# Montana register map
Vendor: ONSemiconductor; Series: Montana Series; File version: 1.0
CPU: CM33 r0p4, little endian, MPU, FPU, 3 interrupt priority bits
Registers are 32-bit, read-write, reset 0x0 unless marked. A register's access mark holds for its fields unless they carry their own. Offsets are from the block's base; [hi:lo] are bit positions; {n}, {i} and the like mark numbered series.

## RESET
Base 0x40000200
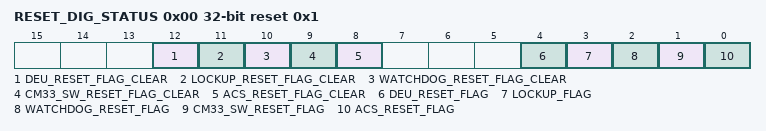
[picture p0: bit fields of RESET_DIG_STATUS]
0x00 RESET_DIG_STATUS reset 0x1 (reset mask 0x1F) — Reset status register
  [12] DEU_RESET_FLAG_CLEAR wo — Reset the sticky DEU reset flag
    1=DEU_RESET_FLAG_CLEAR (Reset the sticky DEU reset flag)
  [11] LOCKUP_RESET_FLAG_CLEAR wo — Reset the sticky LOCKUP flag
    1=LOCKUP_FLAG_CLEAR (Reset the sticky LOCKUP flag)
  [10] WATCHDOG_RESET_FLAG_CLEAR wo — Reset the sticky Watchdog time-out reset flag
    1=WATCHDOG_RESET_FLAG_CLEAR (Reset the sticky Watchdog time-out reset flag)
  [9] CM33_SW_RESET_FLAG_CLEAR wo — Reset the sticky CM33 software reset flag
    1=CM33_SW_RESET_FLAG_CLEAR (Reset the sticky CM33 software reset flag)
  [8] ACS_RESET_FLAG_CLEAR wo — Reset the sticky ACS reset flag
    1=ACS_RESET_FLAG_CLEAR (Reset the sticky ACS reset flag)
  [4] DEU_RESET_FLAG ro — Sticky flag that detect that a DEU reset occured
    0=DEU_RESET_NOT_SET (The DEU reset has not triggered at least once.); 1=DEU_RESET_SET (The DEU reset was triggered at least once since this status bit was last cleared)
  [3] LOCKUP_FLAG ro — Sticky flag that detects that a LOCKUP occurred
    0=LOCKUP_NOT_SET (The LOCKUP has not triggered at least once); 1=LOCKUP_SET (The LOCKUP was triggered at least once)
  [2] WATCHDOG_RESET_FLAG ro — Sticky flag that detects that a Watchdog time-out reset occurred
    0=WATCHDOG_RESET_NOT_SET (The Watchdog time-out reset has not triggered at least once); 1=WATCHDOG_RESET_SET (The Watchdog time-out reset was triggered at least once since this status bit was last cleared)
  [1] CM33_SW_RESET_FLAG ro — Sticky flag that detects that a CM33 software reset occurred
    0=CM33_SW_RESET_NOT_SET (The CM33 software system reset has not triggered at least once); 1=CM33_SW_RESET_SET (The CM33 software system reset was triggered at least once since this status bit was last cleared)
  [0] ACS_RESET_FLAG ro — Sticky flag that detects that a ACS reset occurred
    0=ACS_RESET_NOT_SET (The ACS reset has not triggered at least once); 1=ACS_RESET_SET (The ACS reset was triggered at least once since this status bit was last cleared)

## WATCHDOG — Watchdog Timer
Base 0x40000300
0x00 WATCHDOG_CFG reset 0xB — Watchdog timer Configuration Register
  [3:0] TIMEOUT_VALUE — Watchdog timeout period. Values 0xC to 0xF result in the same timeout period as the value 0xB.
    0=WATCHDOG_TIMEOUT_2M048 (2.048 ms); 1=WATCHDOG_TIMEOUT_4M096 (4.096 ms); 2=WATCHDOG_TIMEOUT_8M2 (8.192 ms); 3=WATCHDOG_TIMEOUT_16M4 (16.384 ms); 4=WATCHDOG_TIMEOUT_32M8 (32.768 ms); 5=WATCHDOG_TIMEOUT_65M5 (65.536 ms); 6=WATCHDOG_TIMEOUT_131M1 (131.072 ms); 7=WATCHDOG_TIMEOUT_262M1 (262.144 ms); 8=WATCHDOG_TIMEOUT_524M3 (524.3 ms); 9=WATCHDOG_TIMEOUT_1048M6 (1.048 sec); 10=WATCHDOG_TIMEOUT_2097M1 (2.097 sec); 11=WATCHDOG_TIMEOUT_4194M3 (4.194 sec)
0x04 WATCHDOG_CTRL reset not defined — Watchdog Refresh Control Register
  [31:0] WATCHDOG_REFRESH wo — Write a key to reset the watchdog
    0x2B1E211=WATCHDOG_REFRESH (Write 32-bit key to reset the watchdog (others values have no effect))
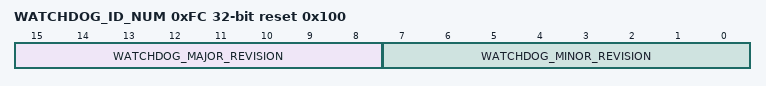
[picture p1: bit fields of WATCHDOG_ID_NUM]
0xFC WATCHDOG_ID_NUM ro reset 0x100 — WATCHDOG ID number
  [15:8] WATCHDOG_MAJOR_REVISION — WATCHDOG Major Revision number
    1=WATCHDOG_MAJOR_REVISION (Watchdog revision 1.0)
  [7:0] WATCHDOG_MINOR_REVISION — WATCHDOG Minor Revision number
    0=WATCHDOG_MINOR_REVISION (Watchdog revision 1.0)

## TIMER0 — General-Purpose Timers
Base 0x40000400
Same registers: TIMER1 0x40000500, TIMER2 0x40000600, TIMER3 0x40000700
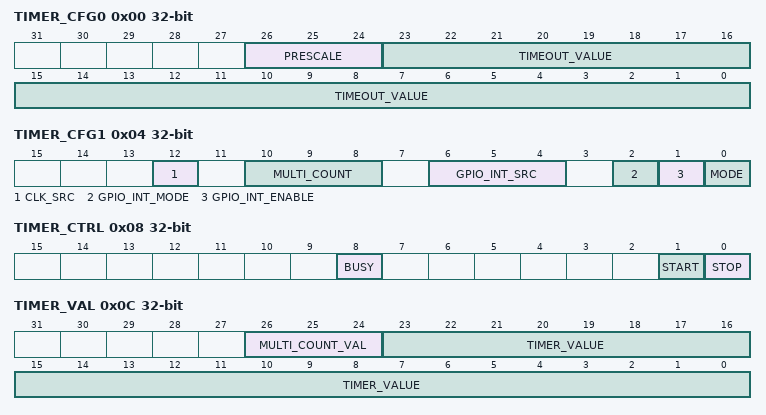
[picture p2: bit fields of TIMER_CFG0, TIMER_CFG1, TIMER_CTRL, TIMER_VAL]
0x00 TIMER_CFG0 — Timer Configuration 0 Register
  [26:24] PRESCALE — Prescale value of the timer
    0=TIMER_PRESCALE_1 (Divide the input clock frequency by 1); 1=TIMER_PRESCALE_2 (Divide the input clock frequency by 2); 2=TIMER_PRESCALE_4 (Divide the input clock frequency by 4); 3=TIMER_PRESCALE_8 (Divide the input clock frequency by 8); 4=TIMER_PRESCALE_16 (Divide the input clock frequency by 16); 5=TIMER_PRESCALE_32 (Divide the input clock frequency by 32); 6=TIMER_PRESCALE_64 (Divide the input clock frequency by 64); 7=TIMER_PRESCALE_128 (Divide the input clock frequency by 128)
  [23:0] TIMEOUT_VALUE — Number of Timer clock cycles to time-out
0x04 TIMER_CFG1 — Timer Configuration 1 Register
  [12] CLK_SRC — Clock source
    0=TIMER_SLOWCLK_DIV32 (Timer clock source is SLOWCLK divided by 32); 1=TIMER_SLOWCLK_DIV2 (Timer clock source is SLOWCLK divided by 2)
  [10:8] MULTI_COUNT — Multi-count value
    0=TIMER_MULTI_COUNT_1 (Stop on 1st Time-out occurrence and issue an interrupt); 1=TIMER_MULTI_COUNT_2 (Stop on 2nd Time-out occurrence and issue an interrupt); 2=TIMER_MULTI_COUNT_3 (Stop on 3rd Time-out occurrence and issue an interrupt); {v}=TIMER_MULTI_COUNT_{v+1} (Stop on {v+1}th Time-out occurrence and issue an interrupt) (v=3..7)
  [6:4] GPIO_INT_SRC — GPIO interrupt source selection
    {v}=TIMER_SRC_GPIO_INT{v} (Select GPIO interrupt defined in GPIO_INT_CFG{v}) (v=0..3)
  [2] GPIO_INT_MODE — GPIO interrupt capture mode
    0=TIMER_GPIO_INT_SINGLE (GPIO interrupt single capture mode); 1=TIMER_GPIO_INT_CONTINUOUS (GPIO interrupt continuous capture mode)
  [1] GPIO_INT_ENABLE — GPIO interrupt capture enable
    0=TIMER_GPIO_INT_DISABLE (Disable GPIO interrupt capture); 1=TIMER_GPIO_INT_ENABLE (Enable GPIO interrupt capture)
  [0] MODE — Timer mode
    0=TIMER_SHOT_MODE (One shot / multi shot mode); 1=TIMER_FREE_RUN (Free-run mode)
0x08 TIMER_CTRL (reset mask 0x100) — General-Purpose timer Control / Status Register
  [8] BUSY ro — Indicate if the timer is active or not
    0=TIMER_INACTIVE (The timer is inactive); 1=TIMER_ACTIVE (The timer is active)
  [1] START wo — Start or restart the timer
    1=TIMER_START (Writing a 1 starts or restarts the timer)
  [0] STOP wo — Stop the timer
    1=TIMER_STOP (Writing a 1 stops the timer)
0x0C TIMER_VAL ro — Timer Current Value Register
  [26:24] MULTI_COUNT_VAL — Current multi counter value
  [23:0] TIMER_VALUE — Current timer value
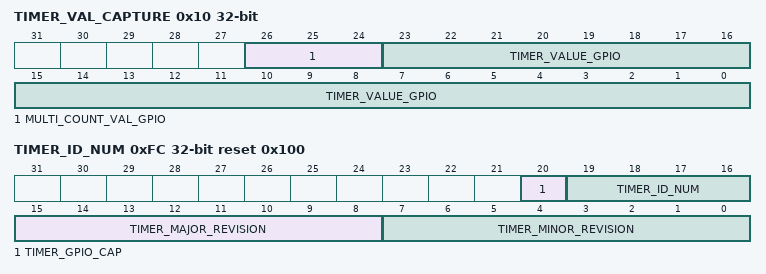
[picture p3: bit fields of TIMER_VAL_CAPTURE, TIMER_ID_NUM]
0x10 TIMER_VAL_CAPTURE — Timer GPIO Interrupt Captured Value Register
  [26:24] MULTI_COUNT_VAL_GPIO — Current multi counter value captured by the GPIO interrupt defined in GPIO_INT_SRC
  [23:0] TIMER_VALUE_GPIO — Timer value captured by the GPIO interrupt defined in GPIO_INT_SRC
0xFC TIMER_ID_NUM ro reset 0x100 — Timer ID number
  [20] TIMER_GPIO_CAP — Implementation of the GPIO triggered capture
    0=TIMER_GPIO_CAP_DISABLED (GPIO capture is not implemented); 1=TIMER_GPIO_CAP_ENABLED (GPIO capture is implemented)
  [19:16] TIMER_ID_NUM — TIMER instance number
  [15:8] TIMER_MAJOR_REVISION — TIMER Major Revision number
    1=TIMER_MAJOR_REVISION (Timer revision 1.0)
  [7:0] TIMER_MINOR_REVISION — TIMER Minor Revision number
    0=TIMER_MINOR_REVISION (Timer revision 1.0)
